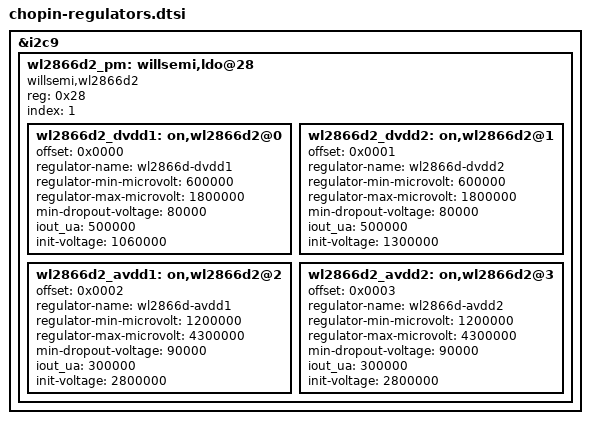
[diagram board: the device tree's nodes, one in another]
/*
 * Copyright (C) 2015 MediaTek Inc.
 *
 * This program is free software: you can redistribute it and/or modify
 * it under the terms of the GNU General Public License version 2 as
 * published by the Free Software Foundation.
 *
 * This program is distributed in the hope that it will be useful,
 * but WITHOUT ANY WARRANTY; without even the implied warranty of
 * MERCHANTABILITY or FITNESS FOR A PARTICULAR PURPOSE. See the
 * GNU General Public License for more details.
 */

/*
 * WL2866D2 PMIC for Chopin display panels and camera power
 * Ported from stock Chopin DTBO fragment@71
 */

&i2c9 {
	wl2866d2_pm: willsemi,ldo@28 {
		compatible = "willsemi,wl2866d2";
		reg = <0x28>;
		index = <1>;
		status = "okay";

		wl2866d2_dvdd1: on,wl2866d2@0 {
			offset = /bits/ 16 <0x0000>;
			regulator-name = "wl2866d-dvdd1";
			regulator-min-microvolt = <600000>;
			regulator-max-microvolt = <1800000>;
			min-dropout-voltage = <80000>;
			iout_ua = <500000>;
			init-voltage = <1060000>;
		};

		wl2866d2_dvdd2: on,wl2866d2@1 {
			offset = /bits/ 16 <0x0001>;
			regulator-name = "wl2866d-dvdd2";
			regulator-min-microvolt = <600000>;
			regulator-max-microvolt = <1800000>;
			min-dropout-voltage = <80000>;
			iout_ua = <500000>;
			init-voltage = <1300000>;
		};

		wl2866d2_avdd1: on,wl2866d2@2 {
			offset = /bits/ 16 <0x0002>;
			regulator-name = "wl2866d-avdd1";
			regulator-min-microvolt = <1200000>;
			regulator-max-microvolt = <4300000>;
			min-dropout-voltage = <90000>;
			iout_ua = <300000>;
			init-voltage = <2800000>;
		};

		wl2866d2_avdd2: on,wl2866d2@3 {
			offset = /bits/ 16 <0x0003>;
			regulator-name = "wl2866d-avdd2";
			regulator-min-microvolt = <1200000>;
			regulator-max-microvolt = <4300000>;
			min-dropout-voltage = <90000>;
			iout_ua = <300000>;
			init-voltage = <2800000>;
		};
	};
};
